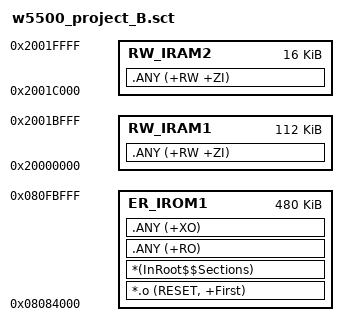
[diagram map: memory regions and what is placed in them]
; *************************************************************
; *** Scatter-Loading for App-B (OTA升级目标区) ***
; *** 链接地址: 0x08084000                       ***
; *************************************************************
; 使用方法: 在Keil中为此配置添加新的Target，使用此scatter文件
; 并在C/C++ Preprocessor中定义: VECT_TAB_OFFSET=0x00084000

#define VECT_TAB_OFFSET_VAL 0x00084000

LR_IROM1 0x08084000 0x00078000  {    ; App-B load region
  ER_IROM1 0x08084000 0x00078000  {  ; execution address
   *.o (RESET, +First)
   *(InRoot$$Sections)
   .ANY (+RO)
   .ANY (+XO)
  }
  RW_IRAM1 0x20000000 0x0001C000  {  ; RW data
   .ANY (+RW +ZI)
  }
  RW_IRAM2 0x2001C000 0x00004000  {
   .ANY (+RW +ZI)
  }
}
